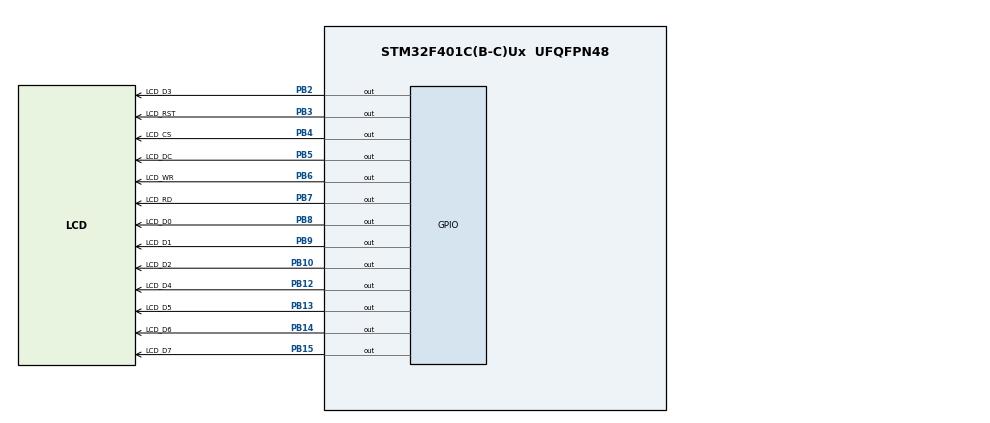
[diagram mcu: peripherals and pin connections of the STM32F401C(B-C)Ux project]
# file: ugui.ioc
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ADC1.Channel-4\#ChannelRegularConversion=ADC_CHANNEL_VREFINT
ADC1.NbrOfConversionFlag=1
ADC1.Rank-4\#ChannelRegularConversion=1
ADC1.SamplingTime-4\#ChannelRegularConversion=ADC_SAMPLETIME_3CYCLES
ADC1.master=1
Dma.Request0=TIM1_UP
Dma.TIM1_UP.0.Direction=DMA_MEMORY_TO_PERIPH
Dma.TIM1_UP.0.FIFOMode=DMA_FIFOMODE_DISABLE
Dma.TIM1_UP.0.Instance=DMA2_Stream5
Dma.TIM1_UP.0.MemDataAlignment=DMA_MDATAALIGN_HALFWORD
Dma.TIM1_UP.0.MemInc=DMA_MINC_ENABLE
Dma.TIM1_UP.0.Mode=DMA_NORMAL
Dma.TIM1_UP.0.PeriphDataAlignment=DMA_PDATAALIGN_HALFWORD
Dma.TIM1_UP.0.PeriphInc=DMA_PINC_DISABLE
Dma.TIM1_UP.0.Priority=DMA_PRIORITY_VERY_HIGH
Mcu.Family=STM32F4
Mcu.Name=STM32F401C(B-C)Ux
Mcu.Package=UFQFPN48
NVIC.DMA2_Stream5_IRQn=true\:0\:0\:false\:false\:true\:false\:true
NVIC.PriorityGroup=NVIC_PRIORITYGROUP_4
PA13.Mode=Serial_Wire
PA13.Signal=SYS_JTMS-SWDIO
PA14.Mode=Serial_Wire
PA14.Signal=SYS_JTCK-SWCLK
PB10.GPIO_Label=LCD_D2
PB10.Signal=GPIO_Output
PB12.GPIO_Label=LCD_D4
PB12.Signal=GPIO_Output
PB13.GPIO_Label=LCD_D5
PB13.Signal=GPIO_Output
PB14.GPIO_Label=LCD_D6
PB14.Signal=GPIO_Output
PB15.GPIO_Label=LCD_D7
PB15.Signal=GPIO_Output
PB2.GPIO_Label=LCD_D3
PB2.Signal=GPIO_Output
PB3.GPIO_Label=LCD_RST
PB3.Signal=GPIO_Output
PB4.GPIO_Label=LCD_CS
PB4.PinState=GPIO_PIN_SET
PB4.Signal=GPIO_Output
PB5.GPIO_Label=LCD_DC
PB5.Signal=GPIO_Output
PB6.GPIO_Label=LCD_WR
PB6.Signal=GPIO_Output
PB7.GPIO_Label=LCD_RD
PB7.PinState=GPIO_PIN_SET
PB7.Signal=GPIO_Output
PB8.GPIO_Label=LCD_D0
PB8.Signal=GPIO_Output
PB9.GPIO_Label=LCD_D1
PB9.Signal=GPIO_Output
PH0\ -\ OSC_IN.Mode=HSE-External-Oscillator
PH0\ -\ OSC_IN.Signal=RCC_OSC_IN
PH1\ -\ OSC_OUT.Mode=HSE-External-Oscillator
PH1\ -\ OSC_OUT.Signal=RCC_OSC_OUT
ProjectManager.HeapSize=0x200
ProjectManager.StackSize=0x400
ProjectManager.TargetToolchain=Makefile
RCC.48MHZClocksFreq_Value=42000000
RCC.ADCPresc=RCC_ADCPCLK2_DIV6
RCC.AHBFreq_Value=84000000
RCC.APB1CLKDivider=RCC_HCLK_DIV2
RCC.APB1Freq_Value=42000000
RCC.APB1TimFreq_Value=84000000
RCC.APB2CLKDivider=RCC_HCLK_DIV2
RCC.APB2Freq_Value=42000000
RCC.APB2TimFreq_Value=84000000
RCC.CortexFreq_Value=84000000
RCC.HCLKFreq_Value=84000000
RCC.HSE_VALUE=25000000
RCC.HSI_VALUE=16000000
RCC.LSE_VALUE=32768
RCC.PLLM=25
RCC.PLLMUL=RCC_PLL_MUL9
RCC.PLLN=168
RCC.PLLSourceVirtual=RCC_PLLSOURCE_HSE
RCC.SYSCLKFreq_VALUE=84000000
RCC.SYSCLKSource=RCC_SYSCLKSOURCE_PLLCLK
RCC.USBFreq_Value=72000000
RCC.VCOOutputFreq_Value=168000000
TIM1.Period=1
VP_ADC1_Vref_Input.Mode=IN-Vrefint
VP_TIM1_VS_ClockSourceINT.Mode=Internal
board=custom

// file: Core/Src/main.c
/* USER CODE BEGIN Header */
/**
  ******************************************************************************
  * @file           : main.c
  * @brief          : Main program body
  ******************************************************************************
  * @attention
  *
  * <h2><center>&copy; Copyright (c) 2020 STMicroelectronics.
  * All rights reserved.</center></h2>
  *
  * This software component is licensed by ST under BSD 3-Clause license,
  * the "License"; You may not use this file except in compliance with the
  * License. You may obtain a copy of the License at:
  *                        opensource.org/licenses/BSD-3-Clause
  *
  ******************************************************************************
  */
/* USER CODE END Header */
#include "main.h"
#include "adc.h"
#include "dma.h"
#include "tim.h"
#include "gpio.h"

/* USER CODE BEGIN Includes */

#include "example.h"
#include "tim_dma.h"

/* USER CODE END Includes */

/* USER CODE BEGIN PV */
/* Private variables ---------------------------------------------------------*/

/* USER CODE END PV */

void SystemClock_Config(void);
/* USER CODE BEGIN PFP */
/* Private function prototypes -----------------------------------------------*/
//extern void initialise_monitor_handles(void); //Linker-Miscellaneous-flags: -specs=rdimon.specs -lc -lrdimon
/* USER CODE END PFP */

/* USER CODE BEGIN 0 */
__align(2) uint16_t dma_buf[20] = {0x5a5a};
/* USER CODE END 0 */

int main(void)
{
  /* USER CODE BEGIN 1 */
  // initialise_monitor_handles();
  // printf("Hello STM32!\n");
  /* USER CODE END 1 */

  /* MCU Configuration--------------------------------------------------------*/

  /* Reset of all peripherals, Initializes the Flash interface and the Systick. */

  LL_APB2_GRP1_EnableClock(LL_APB2_GRP1_PERIPH_SYSCFG);
  LL_APB1_GRP1_EnableClock(LL_APB1_GRP1_PERIPH_PWR);

  NVIC_SetPriorityGrouping(NVIC_PRIORITYGROUP_4);

  /* System interrupt init*/

  /* Configure the system clock */
  SystemClock_Config();

  /* Initialize all configured peripherals */
  MX_GPIO_Init();
  MX_ADC1_Init();
  MX_DMA_Init();
  MX_TIM1_Init();
  /* USER CODE BEGIN 2 */
  SysTick_config(SystemCoreClock/1e3L); // system tick 1ms
  ticks_init();

  Display_Init();
  // Touch_ADC_Init();
  // begin();

  #define Stream 5
  #define TIMx TIM1
  #define DMAx DMA2

  dma_clock_irq(Stream);
  dma_setting(DMAx, Stream);

  // dma_transmit(DMAx, (uint32_t)data, ((uint32_t)&GPIOB->ODR), Stream, 17);
  // TIMx->DIER |= TIM_DIER_UDE; // LL_TIM_EnableDMAReq_UPDATE(TIMx);

  // dma_transmit(DMAx, (uint32_t)dma_buf, ((uint32_t)&GPIOB->ODR), Stream, 20);
  // LL_TIM_EnableDMAReq_UPDATE(TIMx);

  /* USER CODE END 2 */

  /* Infinite loop */
  /* USER CODE BEGIN WHILE */
  begin();
  // for(uint16_t i = 0; i<20; i++) dma_buf[i] = i*0xfa;
  while (1)
  {
    // dma_transmit(DMAx, (uint32_t)dma_buf, ((uint32_t)&GPIOB->ODR), Stream, 20);
    // LL_TIM_EnableDMAReq_UPDATE(TIMx);

    // for(uint16_t i = 0; i<50; i++) __asm volatile ("nop");
    /* USER CODE END WHILE */

    /* USER CODE BEGIN 3 */
    loop();
  }
  /* USER CODE END 3 */
}

void SystemClock_Config(void)
{
  LL_FLASH_SetLatency(LL_FLASH_LATENCY_2);
  while(LL_FLASH_GetLatency()!= LL_FLASH_LATENCY_2)
  {
  }
  LL_PWR_SetRegulVoltageScaling(LL_PWR_REGU_VOLTAGE_SCALE2);
  LL_RCC_HSE_Enable();

   /* Wait till HSE is ready */
  while(LL_RCC_HSE_IsReady() != 1)
  {

  }
  LL_RCC_PLL_ConfigDomain_SYS(LL_RCC_PLLSOURCE_HSE, LL_RCC_PLLM_DIV_25, 168, LL_RCC_PLLP_DIV_2);
  LL_RCC_PLL_Enable();

   /* Wait till PLL is ready */
  while(LL_RCC_PLL_IsReady() != 1)
  {

  }
  LL_RCC_SetAHBPrescaler(LL_RCC_SYSCLK_DIV_1);
  LL_RCC_SetAPB1Prescaler(LL_RCC_APB1_DIV_2);
  LL_RCC_SetAPB2Prescaler(LL_RCC_APB2_DIV_2);
  LL_RCC_SetSysClkSource(LL_RCC_SYS_CLKSOURCE_PLL);

   /* Wait till System clock is ready */
  while(LL_RCC_GetSysClkSource() != LL_RCC_SYS_CLKSOURCE_STATUS_PLL)
  {

  }
  LL_Init1msTick(84000000);
  LL_SetSystemCoreClock(84000000);
  LL_RCC_SetTIMPrescaler(LL_RCC_TIM_PRESCALER_TWICE);
}

void Error_Handler(void)
{
  while(1)
  {
  }
}
